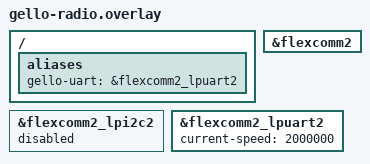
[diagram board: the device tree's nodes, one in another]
/* J1 Arduino D0 RX=P4_3, D1 TX=P4_2. Do NOT use J5/P1_16:
 * this board couples P1_16 to CAN0_RX/P1_11 through R53. */
/ { aliases { gello-uart = &flexcomm2_lpuart2; }; };
&flexcomm2 { status = "okay"; };
&flexcomm2_lpi2c2 { status = "disabled"; };
&flexcomm2_lpuart2 { status = "okay"; current-speed = <2000000>; };
